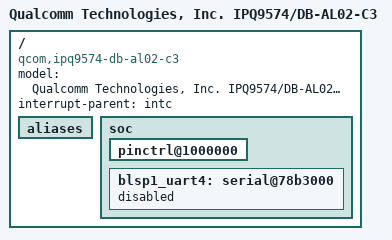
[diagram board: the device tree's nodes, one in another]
// SPDX-License-Identifier: (GPL-2.0+ OR BSD-3-Clause)
/*
 * IPQ9574 DB-AL02-C3 board device tree source
 *
 * Copyright (c) 2020-2021 The Linux Foundation. All rights reserved.
 */

/dts-v1/;

#include "ipq9574-db-al02-c1.dts"

/ {
	#address-cells = <0x2>;
	#size-cells = <0x2>;
	model = "Qualcomm Technologies, Inc. IPQ9574/DB-AL02-C3";
	compatible = "qcom,ipq9574-db-al02-c3", "qcom,ipq9574-db-al02", "qcom,ipq9574";
	interrupt-parent = <&intc>;

	aliases {
		/delete-property/ serial1;
	};

	soc {
		pinctrl@1000000 {
			/delete-node/ ziggy_pins;
		};

		blsp1_uart4: serial@78b3000 {
			/delete-property/ pinctrl-0;
			/delete-property/ pinctrl-names;
			status = "disabled";
		};
	};
};
